# STM32L15xxE register map
File version: 1.0
Registers are 32-bit, read-write, reset 0x0 unless marked. A register's access mark holds for its fields unless they carry their own. Offsets are from the block's base; [hi:lo] are bit positions; {n}, {i} and the like mark numbered series.

## GPIOE — General-purpose I/Os
Base 0x40021000
Same registers: GPIOC 0x40020800, GPIOD 0x40020C00, GPIOH 0x40021400, GPIOF 0x40021800, GPIOG 0x40021C00
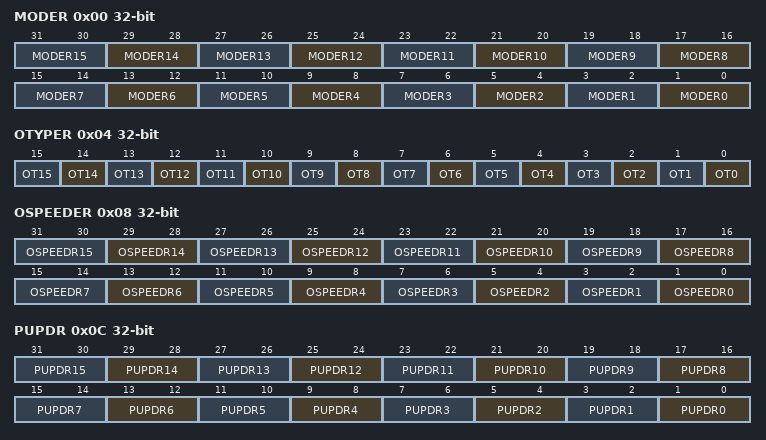
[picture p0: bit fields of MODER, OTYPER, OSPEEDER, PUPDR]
0x00 MODER — GPIO port mode register
  [2n+1:2n] MODER{n} (n=0..15) — Port x configuration bits (y = 0..15)
0x04 OTYPER — GPIO port output type register
  [n] OT{n} (n=0..15) — Port x configuration bits (y = 0..15)
0x08 OSPEEDER — GPIO port output speed register
  [2n+1:2n] OSPEEDR{n} (n=0..15)
0x0C PUPDR — GPIO port pull-up/pull-down register
  [2n+1:2n] PUPDR{n} (n=0..15) — Port x configuration bits (y = 0..15)
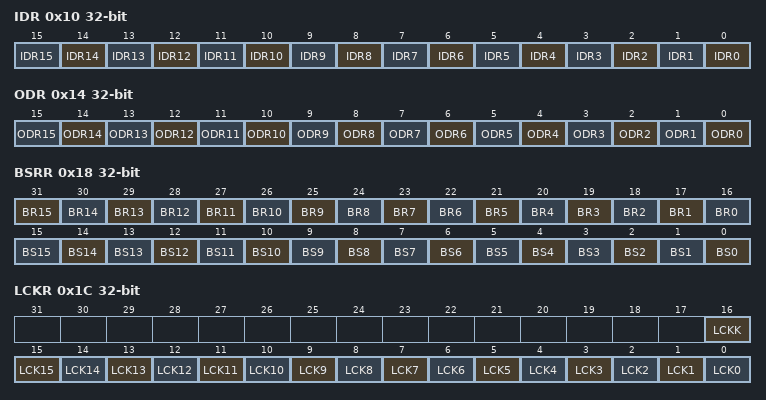
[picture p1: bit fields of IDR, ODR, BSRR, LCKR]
0x10 IDR ro — GPIO port input data register
  [n] IDR{n} (n=0..15) — Port input data (y = 0..15)
0x14 ODR — GPIO port output data register
  [n] ODR{n} (n=0..15) — Port output data (y = 0..15)
0x18 BSRR wo — GPIO port bit set/reset register
  [n+16] BR{n} (n=1..15) — Port x reset bit y (y = 0..15)
  [16] BR0 — Port x set bit y (y= 0..15)
  [n] BS{n} (n=0..15) — Port x set bit y (y= 0..15)
0x1C LCKR — GPIO port configuration lock register
  [16] LCKK — Port x lock bit y (y= 0..15)
  [n] LCK{n} (n=0..15) — Port x lock bit y (y= 0..15)
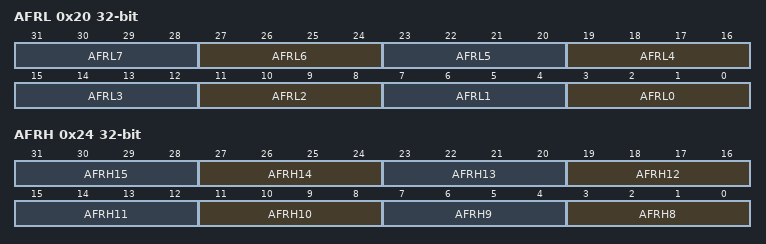
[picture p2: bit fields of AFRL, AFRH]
0x20 AFRL
  [4n+3:4n] AFRL{n} (n=0..7) — Alternate function selection for port x bit y (y = 0..7)
0x24 AFRH — GPIO alternate function high register
  [4n-29:4n-32] AFRH{n} (n=8..15) — Alternate function selection for port x bit y (y = 8..15)

## GPIOA — General-purpose I/Os
Base 0x40020000
Registers as GPIOE; these are added or differ:
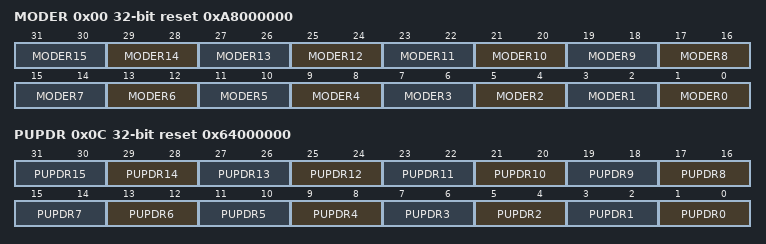
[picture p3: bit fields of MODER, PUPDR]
0x00 MODER reset 0xA8000000 — GPIO port mode register
  [2n+1:2n] MODER{n} (n=0..15) — Port x configuration bits (y = 0..15)
0x0C PUPDR reset 0x64000000 — GPIO port pull-up/pull-down register
  [2n+1:2n] PUPDR{n} (n=0..15) — Port x configuration bits (y = 0..15)

## GPIOB — General-purpose I/Os
Base 0x40020400
Registers as GPIOE; these are added or differ:
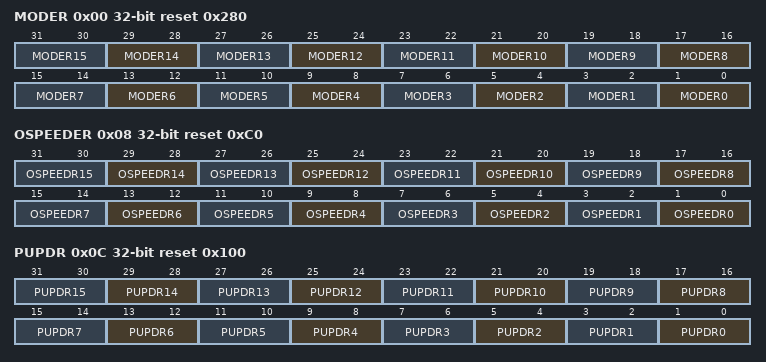
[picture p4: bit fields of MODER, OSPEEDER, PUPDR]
0x00 MODER reset 0x280 — GPIO port mode register
  [2n+1:2n] MODER{n} (n=0..15) — Port x configuration bits (y = 0..15)
0x08 OSPEEDER reset 0xC0 — GPIO port output speed register
  [2n+1:2n] OSPEEDR{n} (n=0..15)
0x0C PUPDR reset 0x100 — GPIO port pull-up/pull-down register
  [2n+1:2n] PUPDR{n} (n=0..15) — Port x configuration bits (y = 0..15)

## TIM9 — General-purpose timers
Base 0x40010800
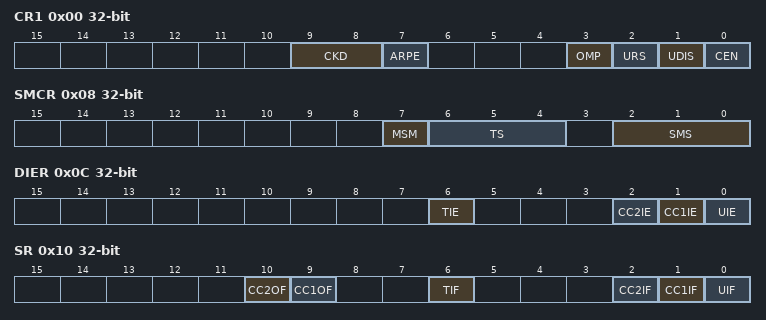
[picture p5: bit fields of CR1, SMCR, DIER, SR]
0x00 CR1 — control register 1
  [9:8] CKD — Clock division
  [7] ARPE — Auto-reload preload enable
  [3] OMP — One-pulse mode
  [2] URS — Update request source
  [1] UDIS — Update disable
  [0] CEN — Counter enable
0x04 CR2 — control register 2
  [6:4] MMS — Master mode selection
0x08 SMCR — slave mode control register
  [7] MSM — Master/Slave mode
  [6:4] TS — Trigger selection
  [2:0] SMS — Slave mode selection
0x0C DIER wo — Interrupt enable register
  [6] TIE — Trigger interrupt enable
  [2] CC2IE — Capture/Compare 2 interrupt enable
  [1] CC1IE — Capture/Compare 1 interrupt enable
  [0] UIE — Update interrupt enable
0x10 SR — status register
  [10] CC2OF — Capture/compare 2 overcapture flag
  [9] CC1OF — Capture/compare 1 overcapture flag
  [6] TIF — Trigger interrupt flag
  [2] CC2IF — Capture/Compare 2 interrupt flag
  [1] CC1IF — Capture/Compare 1 interrupt flag
  [0] UIF — Update interrupt flag
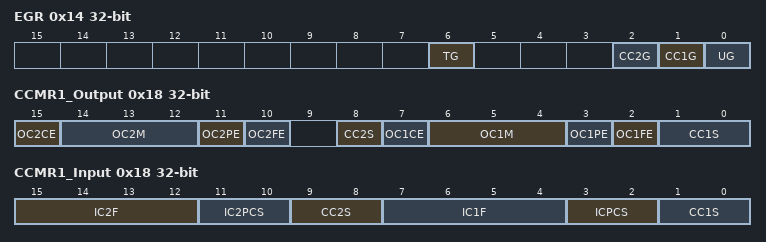
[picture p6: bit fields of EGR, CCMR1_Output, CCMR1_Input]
0x14 EGR — event generation register
  [6] TG — Trigger generation
  [2] CC2G — Capture/Compare 2 generation
  [1] CC1G — Capture/Compare 1 generation
  [0] UG — Update generation
0x18 CCMR1_Output — capture/compare mode register 1
  [15] OC2CE — Output compare 2 clear enable
  [14:12] OC2M — Output compare 2 mode
  [11] OC2PE — Output compare 2 preload enable
  [10] OC2FE — Output compare 2 fast enable
  [8] CC2S — Capture/Compare 2 selection
  [7] OC1CE — Output compare 1 clear enable
  [6:4] OC1M — Output compare 1 mode
  [3] OC1PE — Output compare 1 preload enable
  [2] OC1FE — Output compare 1 fast enable
  [1:0] CC1S — Capture/Compare 1 selection
0x18 CCMR1_Input (alternate view of CCMR1_Output) — capture/compare mode register 1 (input mode)
  [15:12] IC2F — Input capture 2 filter
  [11:10] IC2PCS — Input capture 2 prescaler
  [9:8] CC2S — Capture/Compare 2 selection
  [7:4] IC1F — Input capture 1 filter
  [3:2] ICPCS — Input capture 1 prescaler
  [1:0] CC1S — Capture/Compare 1 selection
0x24 CNT — counter
  [15:0] CNT — TIM9 counter
0x28 PSC — prescaler
  [15:0] PSC — TIM9 prescaler
0x2C ARR — auto-reload register
  [15:0] ARR — Auto-reload value
0x34 CCR1 — capture/compare register 1
  [15:0] CCR1 — Capture/Compare 1 value
0x38 CCR2 — capture/compare register 2
  [15:0] CCR2 — Capture/Compare 2 value
0x50 OR — option register
  [1:0] TI1_RMP — TIM9 Input 1 remapping capability
